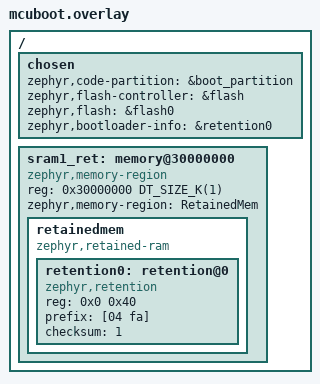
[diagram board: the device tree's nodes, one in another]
/* sysbuild/mcuboot.overlay */

/ {
    chosen {

        zephyr,code-partition = &boot_partition;
        zephyr,flash-controller = &flash; 
        zephyr,flash = &flash0; 
        zephyr,bootloader-info = &retention0; 
    };
    sram1_ret: memory@30000000 {
        compatible = "zephyr,memory-region", "mmio-sram";
        reg = <0x30000000 DT_SIZE_K(1)>;
        zephyr,memory-region = "RetainedMem";
        status = "okay";

        retainedmem {
            compatible = "zephyr,retained-ram";
            status = "okay";
            #address-cells = <1>;
            #size-cells = <1>;

            retention0: retention@0 {
                compatible = "zephyr,retention";
                status = "okay";
                reg = <0x0 0x40>;
                prefix = [04 fa];
                checksum = <1>;
            };
        };
    };
};



